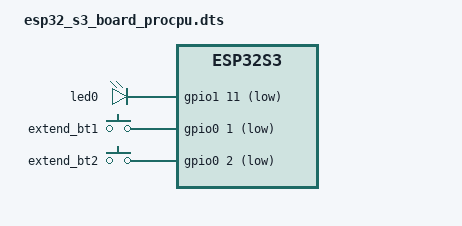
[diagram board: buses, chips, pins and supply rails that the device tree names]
/dts-v1/;

#include <espressif/esp32s3/esp32s3_wroom_n8r8.dtsi>
#include <espressif/partitions_0x0_amp.dtsi>
#include<zephyr/dt-bindings/input/input-event-codes.h>
/* root device tree*/
// hardware object nood
// container nood
// leds/led_0 -> led0

/ {
    leds {
        compatible = "gpio-leds";
        led0: led_0 {
            gpios = <&gpio1 11 GPIO_ACTIVE_LOW>;
        };
    };

    gpio_keys: gpio-keys {
        compatible = "gpio-keys";
        debounce-interval-ms = <20>;
        
        extend_bt1: e_bt1{
            gpios = <&gpio0 1 (GPIO_ACTIVE_LOW | GPIO_PULL_UP)>;
            zephyr,code = <INPUT_KEY_A>;
        };
        extend_bt2: e_bt2{
            gpios = <&gpio0 2 (GPIO_ACTIVE_LOW | GPIO_PULL_UP)>;
            zephyr,code = <INPUT_KEY_B>;
        };
    };

    aliases {
        led0 = &led0;
    };

    chosen {
        zephyr,sram = &sram1;
        zephyr,flash = &flash0;  
        zephyr,console = &uart0;      
    };

};

&gpio1 {
    status = "okay";
};
&gpio0 {
    status = "okay";
};

/* esp32 clock is done defult
&clock {
    clocks = <&fast-clk-src>;
    status = "okay";
};
*/

/* power is done defult
&pwr {

};
*/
